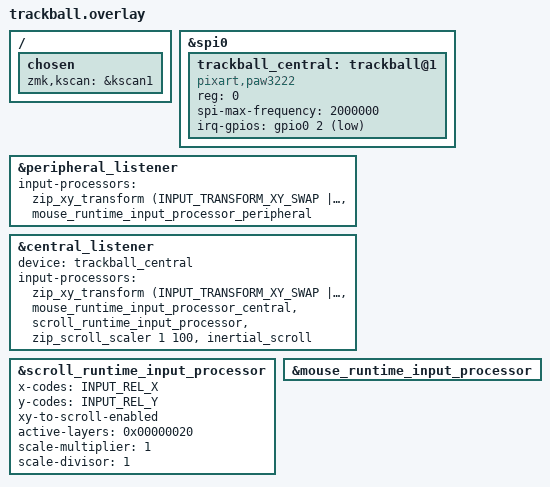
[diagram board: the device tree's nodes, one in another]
#include "../lism-input-processors.dtsi"

/ {
    chosen {
        zmk,kscan = &kscan1;
    };
};

&spi0 {
    status = "okay";

    trackball_central: trackball@1 {
        status = "okay";
        compatible = "pixart,paw3222";
        reg = <0>;
        spi-max-frequency = <2000000>;
        irq-gpios = <&gpio0 2 (GPIO_ACTIVE_LOW | GPIO_PULL_UP)>;
    };
};

// ペリフェラル側のリスナー有効化
&peripheral_listener {
    status = "okay";
    input-processors = <&zip_xy_transform (INPUT_TRANSFORM_XY_SWAP | INPUT_TRANSFORM_X_INVERT) &mouse_runtime_input_processor_peripheral>;  
};

// セントラルのリスナー設定
&central_listener {
    status = "okay";
    device = <&trackball_central>;
    input-processors = <
        &zip_xy_transform (INPUT_TRANSFORM_XY_SWAP | INPUT_TRANSFORM_Y_INVERT) 
        &mouse_runtime_input_processor_central
        &scroll_runtime_input_processor &zip_scroll_scaler 1 100 &inertial_scroll
    >;
};

/* ─────────────────────────────────────────────────────────────
   scroll_runtime_input_processor をスクロール変換器として上書き
   ────────────────────────────────────────────────────── */
&scroll_runtime_input_processor {
    x-codes = <INPUT_REL_X>;
    y-codes = <INPUT_REL_Y>;
    xy-to-scroll-enabled;
    active-layers = <0x00000020>; /* layer5 */
    scale-multiplier = <1>;
    scale-divisor = <1>;   /* Studio UI の倍率がそのまま実効値 (1.0x基準) */
};

&mouse_runtime_input_processor {
};
